# ISP_CCDC register map
Vendor: Texas Instruments
Peripheral module from a debugger description file (folder omap36xx).
Registers are 32-bit, read-write, reset 0x0 unless marked. A register's access mark holds for its fields unless they carry their own. Offsets are as the file gives them; lines under a group give offsets from that group; [hi:lo] are bit positions; {n}, {i} and the like mark numbered series; 'fields as' and 'values as' point back to an identical list; <NAME> marks a mode.

## ISP_CCDC
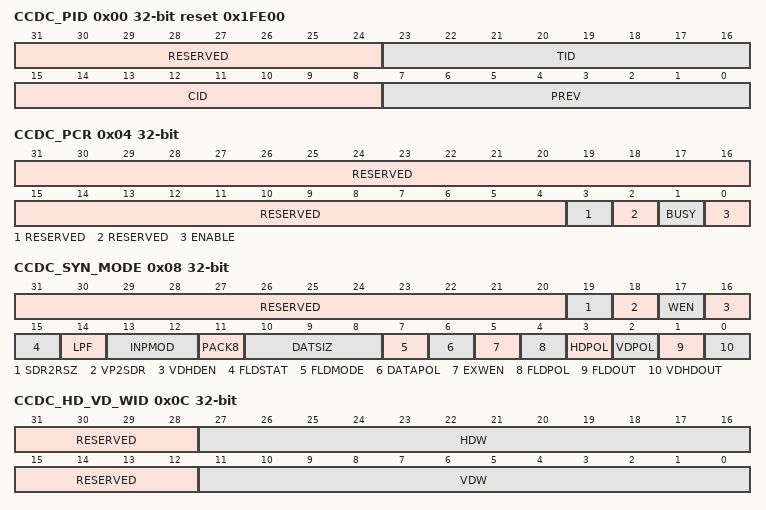
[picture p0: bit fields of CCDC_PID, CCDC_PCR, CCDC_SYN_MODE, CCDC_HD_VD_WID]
0x00 CCDC_PID ro reset 0x1FE00 (reset mask 0xFFFFFF00) — PERIPHERAL ID REGISTER
  [31:24] RESERVED — Write 0s for future compatibility. Reads returns 0.
  [23:16] TID — Peripheral identification: CCDC module
  [15:8] CID — Class identification: Camera ISP
  [7:0] PREV — Peripheral revision number
0x04 CCDC_PCR access per field — PERIPHERAL CONTROL REGISTER
  [31:4] RESERVED rw — Write 0s for future compatibility.Reads returns 0.
  [3] RESERVED rw — Write 0s for future compatibility. Read returns 0.
  [2] RESERVED rw — Write 0s for future compatibility. Read returns 0.
  [1] BUSY ro — CCDC module busy.
    0=Module is not busy; 1=Module is busy
  [0] ENABLE rw — CCDC module enable.This bit is latched by VD (start of frame)
    0=Disable module; 1=Enable module
0x08 CCDC_SYN_MODE access per field — SYNC and mode set register
  [31:20] RESERVED rw — Write 0s for future compatibility.Reads returns 0.
  [19] SDR2RSZ rw — Memory port output into the RESIZER input. Controls whether or not the memory port output data are forwarded to the RESIZER module input port. This does not depend on the state of the CCDC_SYN_MODE.WEN bit. This bit must only be set if the CCDC module receives directly YUV422 data. The input frame size to the RESIZER module is the same as the output frame size to the memory port. The data are simultaneously written to memory if the WEN bit is set while sending the same data to the RESIZER module. The PREVIEW module can also write to the RESIZER module: this bit takes precedence over the PREVIEW module settings. This bit is latched by the VS sync pulse.
    0=Disable; 1=Enable
  [18] VP2SDR rw — Video port output enable to the output formatter.. Controls whether the video port data is forwarded to the output formatter or not. If CCDC_SYN_MODE .WEN= 1, the video port data is written to memory. Note that if field is set, then SDRAM line (VERT_START.SLVx) and pixel start (HORZ_INFO.SPH) are with respect to the video port output (and not the original input) This bit field is latched by the VS sync pulse.
    0=Disable; 1=Enable
  [17] WEN rw — Data write enable. Controls whether the CCDC module output data are written to memory or not. This bit field is latched by the VS sync pulse.
    0=Disable; 1=Enable
  [16] VDHDEN rw — Timing generator enable. If HS/VS sync pulses are defined as output signals, activates the internal timing generator. If HS/VS sync pulses are defined as input signals, activates internal timing generator to synchronize with HS/VS. This bit must be set to 1 when HS and VS signals are used.
    0=Disable; 1=Enable
  [15] FLDSTAT ro — cam_fld signal status. This bit field applies only if the CCDC module is configured to work in interlaced mode: CCDC_SYN_MODE.FLDMODE = 'interlaced'. It indicates the status of the current field.
    0=Odd field; 1=Even field
  [14] LPF rw — Three-tap low pass (antialiasing) filter enable. This bit field is latched by the VS sync pulse.
    0=Filter is disabled; 1=Filter is enabled
  [13:12] INPMOD rw — cam_d format in SYNC mode. Sets the data input format.
    0=Raw data; 1=YCbCr data on 16 bits. It is required to enable the 8 to 16-bit bridge in the register.; 2=YCbCr data on 8 bits
  [11] PACK8 rw — Data packing. Sets the data packing configuration when the data is written to memory.
    0=Normal mode: 16 bits/pixel; 1=Pack mode: 8 bits/pixel
  [10:8] DATSIZ rw — cam_d signal width in SYNC mode. Valid only when CCDC_SYN_MODE.INPMOD = 'raw data'.
    0=cam_d is 8 bits but the 8 to 16-bit bridge is enabled in the register; 4=cam_d is 12 bits; 5=cam_d is 11 bits; 6=cam_d is 10 bits; 7=cam_d is 8 bits
  [7] FLDMODE rw — cam_fld signal mode.
    0=Progressive mode. cam_fld not used.; 1=Interlaced mode. cam_fld used.
  [6] DATAPOL rw — cam_d signal polarity.
    0=Normal; 1=One's complement
  [5] EXWEN rw — External write enable selection. The cam_wen signal can be used as an external memory write-enable signal. The data is stored to memory only if cam_hs, cam_vs and cam_wen signals are asserted.
    0=cam_wen is not used; 1=cam_wen is used
  [4] FLDPOL rw — cam_fld signal polarity.
    0=Positive; 1=Negative
  [3] HDPOL rw — Sets the cam_hs signal polarity.
    0=Positive; 1=Negative
  [2] VDPOL rw — cam_vs signal polarity
    0=Positive; 1=Negative
  [1] FLDOUT rw — cam_fld signal direction.
    0=Input; 1=Output
  [0] VDHDOUT rw — cam_hs and cam_vs signal directions.
    0=Input; 1=Output
0x0C CCDC_HD_VD_WID — SYNC WIDTH CONTROL REGISTER
  [31:28] RESERVED — Write 0s for future compatibility.Reads returns 0.
  [27:16] HDW — Sets the width of the HS sync pulse if set as output. The width of the pulse is (HDW+1) pixel clocks. Not used when HS/VS sync pulses are input signals (CCDC_SYN_MODE.VDHDOUT = 0). This bit field is latched by the VS sync pulse.
  [15:12] RESERVED — Write 0s for future compatibility.Reads returns 0.
  [11:0] VDW — Sets the width of the VS sync pulse is set as output. The width of the pulse is (VDW+1) lines. Not used when HS/VS sync pulses are input signals (CCDC_SYN_MODE.VDHDOUT = 0). This bit field is latched by the VS sync pulse.
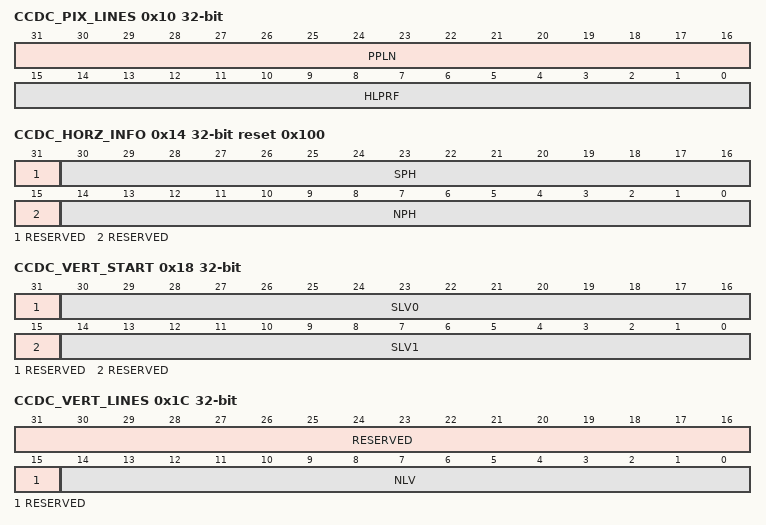
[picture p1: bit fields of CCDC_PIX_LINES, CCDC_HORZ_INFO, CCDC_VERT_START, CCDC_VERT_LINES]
0x10 CCDC_PIX_LINES — SIZE CONTROL REGISTER
  [31:16] PPLN — Pixels per line Sets the number of pixel clock periods in one line. HD period = (PPLN + 1) pixel clocks. Not used when HS/VS sync pulses are input signals (CCDC_SYN_MODE.VDHDOUT = 0). This bit field is latched by the VS sync pulse
  [15:0] HLPRF — Half line per field or frame Sets the number of half lines per frame or field. VD period = (HLPFR + 1)/2 lines. Not used when HS/VS sync pulses are input signals (CCDC_SYN_MODE.VDHDOUT = 0). Sets the internal timing generator to generate the correct number of HS pulses in between two VS pulses. If the sensor is interlaced, with a total of N lines, then this field must be set to N. This means that N half lines are written for each field. If the sensor is progressive, then this register must be set to be twice the number of lines to be written. For example, if sensor outputs N lines, this field must be set to 2N. This bit field is latched by the VS sync pulse.
0x14 CCDC_HORZ_INFO reset 0x100 — HORIZONTAL PIXEL INFO REGISTER
  [31] RESERVED — Write 0s for future compatibility.Reads returns 0.
  [30:16] SPH — Start pixel horizontal Sets the pixel clock position at which data output to memory begins. It is measured from the start of HS. This bit field is latched by the VS sync pulse.
  [15] RESERVED — Write 0s for future compatibility.Reads returns 0.
  [14:0] NPH — Number of pixels horizontal Sets the number of horizontal pixels output to memory. The number of pixels output is (NPH + 1). This bit field is latched by the VS sync pulse.
0x18 CCDC_VERT_START — VERTICAL LINE START REGISTER
  [31] RESERVED — Write 0s for future compatibility.Reads returns 0.
  [30:16] SLV0 — Start line vertical - field0 Sets the line at which data output to memory begins. It is measured from the start of the VS sync pulse. This bit field is latched by the VS sync pulse.
  [15] RESERVED — Write 0s for future compatibility.Reads returns 0.
  [14:0] SLV1 — Start line vertical - field1 Sets the line at which data output to memory begins. It is measured from the start of the VS sync pulse. For a progressive sensor, this bit field is ignored. This bit field is latched by the VS sync pulse.
0x1C CCDC_VERT_LINES — VERTICAL LINE NUMBER REGISTER
  [31:15] RESERVED — Write 0s for future compatibility.Reads returns 0.
  [14:0] NLV — Number of lines - vertical direction Sets the number of vertical lines output to memory. The number of lines output is (NLV + 1). This bit is latched by the VS sync pulse.
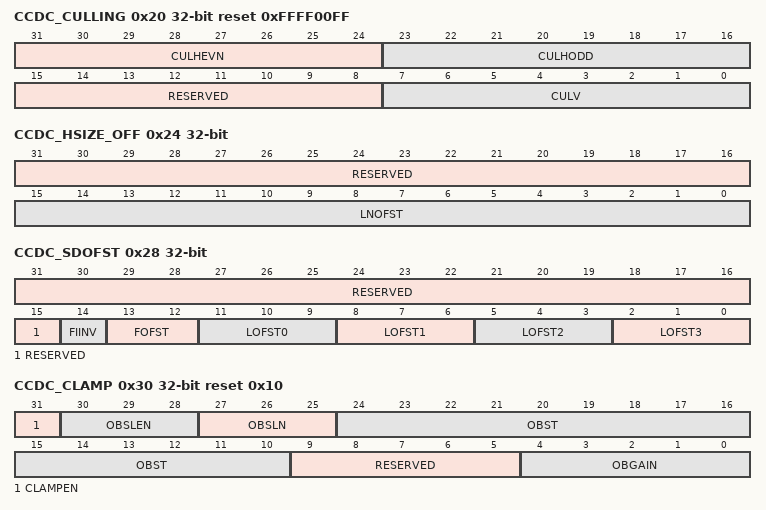
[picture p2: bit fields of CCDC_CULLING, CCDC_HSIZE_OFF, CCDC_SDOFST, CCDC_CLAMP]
0x20 CCDC_CULLING reset 0xFFFF00FF — CULL CONTROL REGISTER
  [31:24] CULHEVN — Horizontal culling patterns for even lines. Sets an 8-bit mask (0:cull, 1:retain). The LSB is the 1st pixel and the MSB is the 8th pixel. Then, the pattern repeats. This bit field is latched by the VS sync pulse.
  [23:16] CULHODD — Horizontal culling patterns for odd lines. Sets an 8-bit mask (0:cull, 1:retain). The LSB is the 1st pixel and the MSB is the 8th pixel. Then, the pattern repeats. This bit field is latched by the VS sync pulse.
  [15:8] RESERVED — Write 0s for future compatibility.Reads returns 0.
  [7:0] CULV — Vertical culling pattern. Sets an 8-bit mask (0:cull, 1:retain). The LSB is the 1st line and the MSB is the 8th line. Then, the pattern repeats. This bit field is latched by the VS sync pulse.
0x24 CCDC_HSIZE_OFF — HORIZONTAL SIZE REGISTER
  [31:16] RESERVED — Write 0s for future compatibility.Reads returns 0.
  [15:0] LNOFST — Line offset. Sets the offset for each output line to memory. The offset must be a multiple of 32 bytes: the 5 least significant bits are ignored. Usually the line offset is equal to the line length in bytes, that is, the line length must be a multiple of 32 bytes. If LNOFST = 0, the data is written again and again over the same line. For optimal performance in the system, the address offset must be on a 256-byte boundary. This bit field is latched by the VS sync pulse.
0x28 CCDC_SDOFST — MEMORY OFFSET REGISTER
  [31:15] RESERVED — Write 0s for future compatibility.Reads returns 0.
  [14] FIINV — Field identification signal inverse This bit field is latched by the VS sync pulse.
    0=Non inverse; 1=Inverse
  [13:12] FOFST — Line offset value This bit field is latched by the VS sync pulse.
    0=+1 line; 1=+2 lines; 2=+3 lines; 3=+4 lines
  [11:9] LOFST0 — Line offset values of even lines and even fields(field id = 0). This bit field is latched by the VS sync pulse.
    0=+1 line; 1=+2 lines; 2=+3 lines; 3=+4 lines; 4=-1 line; 5=-2 lines; 6=-3 lines; 7=-4 lines
  [8:6] LOFST1 — Line offset values of odd lines and even fields(field id = 0). This bit field is latched by the VS sync pulse.
    values as LOFST0
  [5:3] LOFST2 — Line offset values of even lines and odd fields(field id = 1). This bit field is latched by the VS sync pulse.
    values as LOFST0
  [2:0] LOFST3 — Line offset values of odd lines and odd fields(field id = 1). This bit field is latched by the VS sync pulse.
    values as LOFST0
0x2C CCDC_SDR_ADDR — MEMORY ADDRESS REGISTER
  [31:0] ADDR — Memory address Sets the CCDC module output address. The address should be aligned on a 32-byte boundary: the 5 least significant bits are ignored. For optimal performance in the system, the address must be on a 256-byte boundary. This bit field is latched by the VS sync pulse.
0x30 CCDC_CLAMP reset 0x10 — CLAMP CONTROL REGISTER
  [31] CLAMPEN — Clamp enable Enables clamping based on the calculated average of optical black sample. This bit is latched by the VS sync pulse.
    0=Disable; 1=Enable
  [30:28] OBSLEN — Optical black sample length Sets the number of optical black sample pixels per line to include in the average calculation.
    0=1 pixel; 1=2 pixels; 2=4 pixels; 3=8 pixels; 4=16 pixels
  [27:25] OBSLN — Optical black sample lines Sets the number of optical black sample lines to include in the average calculation.
    0=1 line; 1=2 lines; 2=4 lines; 3=8 lines; 4=16 lines
  [24:10] OBST — Start pixel of optical black samples Start pixel position of optical black samples specified from the start of HS in pixel clocks.
  [9:5] RESERVED — Write 0s for future compatibility.Reads returns 0.
  [4:0] OBGAIN — Gain to apply to the optical black average The gain value is in U5Q4 fixed point representation (0 to 1.9375).
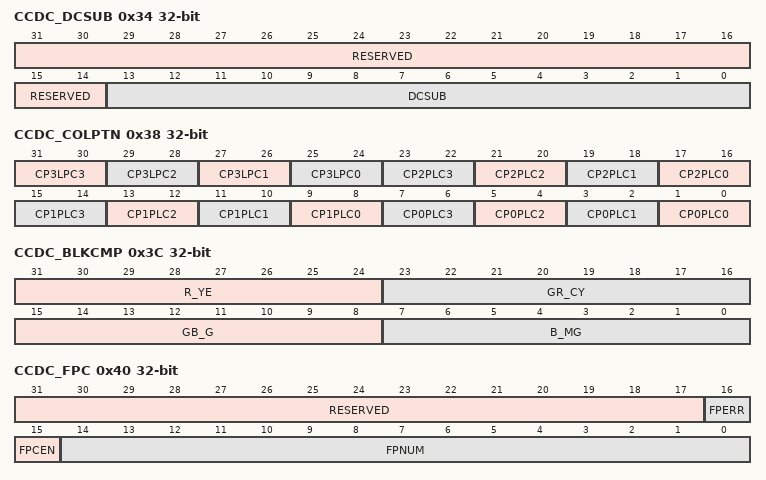
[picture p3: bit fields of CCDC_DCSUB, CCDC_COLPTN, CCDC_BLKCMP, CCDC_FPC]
0x34 CCDC_DCSUB — DC CLAMP REGISTER
  [31:14] RESERVED — Write 0s for future compatibility.Reads returns 0.
  [13:0] DCSUB — DC value to subtract from the data. Sets the DC value to be subtracted from the data when optical black sampling is disabled: CCDC_CLAMP.CLAMPEN = 0 NOTE: In ISP2 thas is the legacy device, this function does not clip negative results to 0 for YUV 8 bit input or REC656 input modes (CCDC_SYN_MODE.INPMOD == 2 || CCDC_REC656IF.R656ON == 1).
0x38 CCDC_COLPTN — COLOR PATTERN REGISTER
  [all] fields
    0=R/Ye; 1=Gr/Cy; 2=Gb/G; 3=B/Mg
  [31:30] CP3LPC3 — Color pattern, 3rd line, pixel counter = 0
  [29:28] CP3LPC2 — Color pattern, 3rd line, pixel counter = 2
  [27:26] CP3LPC1 — Color pattern, 3rd line, pixel counter = 1
  [25:24] CP3LPC0 — Color pattern, 3rd line, pixel counter = 0
  [2n+17:2n+16] CP2PLC{n} (n=0..3) — Color pattern, 2nd line, pixel counter = {n}
  [2n+9:2n+8] CP1PLC{n} (n=0..3) — Color pattern, 1st line, pixel counter = {n}
  [2n+1:2n] CP0PLC{n} (n=0..3) — Color pattern, 0th line, pixel counter = {n}
0x3C CCDC_BLKCMP — BLACK COMPENSATION REGISTER
  [31:24] R_YE — Black-level compensation, R/Ye pixels. 2's complement, MSB is sign bit. The range is -128 to +127.
  [23:16] GR_CY — Black-level compensation, Gr/Cy pixels. 2's complement, MSB is sign bit. The range is -128 to +127.
  [15:8] GB_G — Black-level compensation, Gb/G pixels. 2's complement, MSB is sign bit. The range is -128 to +127.
  [7:0] B_MG — Black-level compensation, B/Mg pixels. 2's complement, MSB is sign bit. The range is -128 to +127.
0x40 CCDC_FPC — FAULT PIXEL CORRECTION REGISTER
  [31:17] RESERVED — Write 0s for future compatibility.Reads returns 0.
  [16] FPERR — Fault pixel correction error This bit is set when the CCDC module is unable to fetch the required fault pixel table entry in time. Write 1 to clear the error or end_of_frame clears it automatically for the next frame. For example, the current pixel being processed has coordinates of 256/512 (256th line and 512th pixel in that line) and it must be corrected. If the entry in the fault pixel table that must be used has coordinates 256/256, then the current pixel cannot be corrected since the correct entry is not loaded in time. Note that there is no error recovery mechanism in the CCDC; if this bit is set at anytime in a frame, there are no more fault pixels corrected in that frame. Firmware is responsible for making sure that there is enough bandwidth in the system to allow for loading of the fault pixel table. Alternately, decreasing the frequency of the fault pixels to be corrected enhances the chances of this bit not being set.
    0=No error; 1=Error
  [15] FPCEN — Fault pixel correction enable. Upon setting this bit, and as long as it remains enabled, the fault pixel logic continues to request data and just start over for next frame once the last data of current frame has been received. As soon as the register is set the data are fetched. To disable fault pixel correction, users can write a 0 at any time. However, the disabling only applies after the current frame is processed (busy bit for current frame is 0) This bit should only be written after the FPC_ADDR register below has been set. Also, the other fields in this register have to be set prior to enabling this bit. The required process is: Write(FPC_ADDR)Write(FPC) with this bit (FPC.FPCEN) turned offWrite(FPC) with this bit (FPC.FPCEN) turned on while other fields are same as previous write
    0=Disable; 1=Enable
  [14:0] FPNUM — Number of fault pixels to be corrected in the frame This field should not be changed when the FPCEN is enabled at any time
0x44 CCDC_FPC_ADDR — FAULT PIXEL CORRECTION MEMORY ADDRESS
  [31:0] ADDR — Memory address Set the memory address of the fault pixel correction table. The address should be aligned to a 64-byte boundary: the 6 LSBs are ignored. Each of the 32-bit table entry contains a 13-bit vertical position, a 14-bit horizontal position and a 5-bit operation field.
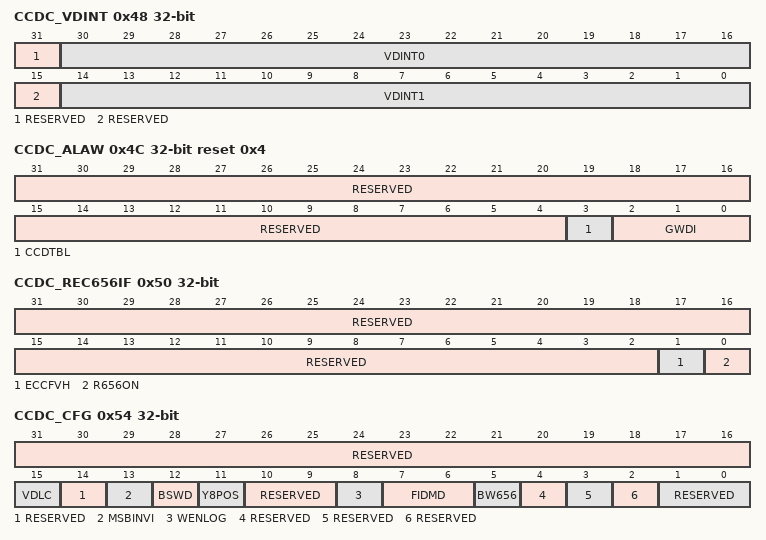
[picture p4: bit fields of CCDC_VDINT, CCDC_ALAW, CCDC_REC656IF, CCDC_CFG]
0x48 CCDC_VDINT — VD INTERRUPT REGISTER
  [31] RESERVED — Write 0s for future compatibility.Reads returns 0.
  [30:16] VDINT0 — VD0 interrupt timing Specified VDINT0 in units of horizontal lines from the start of the VS sync pulse. The resulting value is VDINT0+1. Note that if the rising edge (or falling edge if programmed) of the HS sync pulse lines up with the rising edge (or falling edge if programmed) of VS sync pulse, the first HS sync pulse is not counted.
  [15] RESERVED — Write 0s for future compatibility.Reads returns 0.
  [14:0] VDINT1 — VD1 interrupt timing Specifies VDINT1 in units of horizontal lines from the start of the VS sync pulse. The resulting value is VDINT1+1. Note that if the rising edge (or falling edge if programmed) of the HS sync pulse lines up with the rising edge (or falling edge if programmed) of VS sync pulse, the first HS sync pulse is not counted.
0x4C CCDC_ALAW reset 0x4 — ALAW SETTINGS REGISTER
  [31:4] RESERVED — Write 0s for future compatibility.Reads returns 0.
  [3] CCDTBL — Apply A-Law compression to data saved to memory.
    0=Disable; 1=Enable
  [2:0] GWDI — A-Law input width
    3=Bits 12 to 3; 4=Bits 11 to 2; 5=Bits 10 to 1; 6=Bits 9 to 0
0x50 CCDC_REC656IF — ITU-R BT.656 CONFIGURATION REGISTER
  [31:2] RESERVED — Write 0s for future compatibility.Reads returns 0.
  [1] ECCFVH — FVH error correction enable
    0=Disable; 1=Enable
  [0] R656ON — ITU-R BT656 interface enable
    0=Disable; 1=Enable
0x54 CCDC_CFG — CONFIGURATION REGISTER
  [31:16] RESERVED — Write 0s for future compatibility.Reads returns 0.
  [15] VDLC — Enable latching function registers on the internal VS sync pulse. If this bit is set, all the register fields that are VS pulse latched take on new values immediately. Care should be taken not to alter fields that can cause undesired behavior to the output data NOTE: In ISP2 that is in the legacy device, this bit must be set to 1 by software if the CCDC is to be used. If CCDCFG.VDLC remains set to 0 (default), indeterminate results may occur for ANY register access in the CCDC. For details, see , .
    0=Latched on VS; 1=Not latched on VS
  [14] RESERVED — Write 0s for future compatibility.Reads returns 0.
  [13] MSBINVI — MSB of chroma input signal stored to memory inverted.
    0=Normal; 1=MSB inverted
  [12] BSWD — Byte swap data stored to memory.
    0=Normal; 1=Swap bytes
  [11] Y8POS — Location of Y color component when YCbCr 8-bit data is input.
    0=Even pixel; 1=Odd pixel
  [10:9] RESERVED — Write 0s for future compatibility.Reads returns 0.
  [8] WENLOG — Valid area settings
    0=Internal valid signal and WEN signal are ANDed logically; 1=Internal valid signal and WEN signal are ORed logically
  [7:6] FIDMD — Settings of field identification detection function.
    0=FLD signal is latched at the VS timing. The external Field signal is latched when the VD is active and the active edge of the HD signal; 1=FLD signal is not latched. The field signal is not latched at all; 2=FLD signal is latched at edge of VS. The field signal is latched on the active edge of the VD signal; 3=FLD signal is latched on phase of VS and HS. The field signal is latched when the VD signal is active and the HD signal is inactive (opposite phase)
  [5] BW656 — The data width in ITU-R BT656 input mode. This bit field takes precedence over the CCDC_SYN_MODE.INPMOD and CCDC_DATSIZ bit fields if the ITU mode is enabled with CCDC_REC656IF.R656ON = 1.
    0=8 bits; 1=10 bits
  [4] RESERVED — Write 0s for future compatibility.Reads returns 0.
  [3] RESERVED — Write 0s for future compatibility.Reads returns 0.
  [2] RESERVED — Write 0s for future compatibility.Reads returns 0.
  [1:0] RESERVED — Write 0s for future compatibility.Reads returns 0.
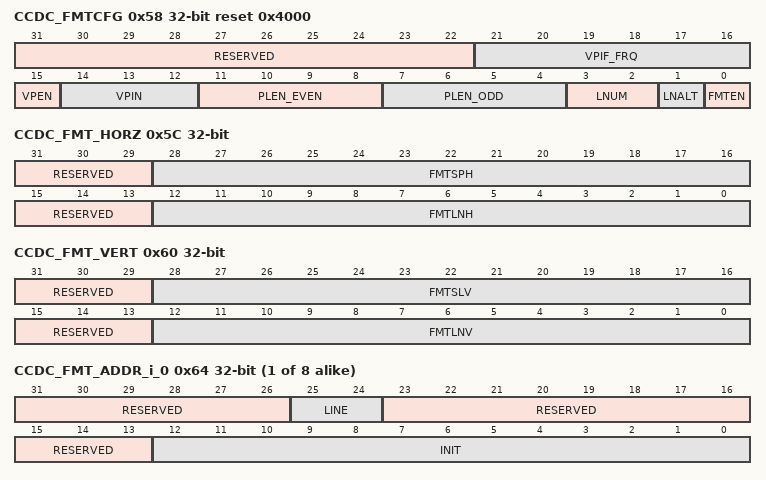
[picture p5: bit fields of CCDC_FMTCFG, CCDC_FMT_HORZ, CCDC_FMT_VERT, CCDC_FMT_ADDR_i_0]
0x58 CCDC_FMTCFG access per field reset 0x4000 — DATA REFORMATTER/VIDEO IF CONFIG REGISTER
  [31:22] RESERVED ro — Write 0s for future compatibility. Read returns 0.
  [21:16] VPIF_FRQ rw — Video port data ready frequency. This field allows the firmware to control the rate at which the video port delivers new data to the other modules (PREVIEW, H3A, and HIST modules). In effect, this register controls the raw output bandwidth of the PREVIEW, H3A, and HIST. Depending on the input sensor clock, the user can set this field appropriately and balance the bandwidth requirements to memory. Given a pixel clock, one shall set this bit field with the higher divisor value to lower the memory bandwidth requirement. The video port clock is Interconnect/(VPIF_FRQ+2).The valid range for VPIF_FRQ is 0..62
  [15] VPEN rw — Video port enable. This bit shall be enabled to send data to the PREVIEW, H3A and HIST modules.
    0=Disable; 1=Enable
  [14:12] VPIN rw — 10-bit input select for video port.
    3=bits 12-3; 4=bits 11-2; 5=bits 10-1; 6=bits 9-0
  [11:8] PLEN_EVEN rw — Number of program entries in even line minus 1. If the desired number of program entries is 8, then the value shall be set to 7.
  [7:4] PLEN_ODD rw — Number of program entries in odd line minus 1. If the desired number of program entries is 8, then the value shall be set to 7.
  [3:2] LNUM rw — Number of output lines from 1 input line
    0=1 line; 1=2 lines; 2=3 lines; 3=4 lines
  [1] LNALT rw — Line alternating mode enable.In Line Alternating Mode, even and odd lines are swapped. 0th line output as 1st line and 1st line output as 0th line, and so on. If this bit field is set, the start and number of lines for the formatter (FMTVERT below) should be even. The FMTEN field below should be set in addition for this field to function
    0=Enable. Normal mode; 1=Disable. Line alternating mode
  [0] FMTEN rw — Formatter enable. This bit is latched by the VS sync pulse.
    0=Disable; 1=Enable
0x5C CCDC_FMT_HORZ — DATA REFORMATTER HORIZ INFO REGISTER
  [31:29] RESERVED — Write 0s for future compatibility.Reads returns 0.
  [28:16] FMTSPH — Start pixel horizontal from start of the HS sync pulse.
  [15:13] RESERVED — Write 0s for future compatibility.Reads returns 0.
  [12:0] FMTLNH — Number of pixels in horizontal direction to use for the data reformatter (minimum is 2 pixels).
0x60 CCDC_FMT_VERT — DATA REFORMATTER VERT INFO REGISTER
  [31:29] RESERVED — Write 0s for future compatibility.Reads returns 0.
  [28:16] FMTSLV — Start line from start of VS sync pulse for the data reformatter.
  [15:13] RESERVED — Write 0s for future compatibility.Reads returns 0.
  [12:0] FMTLNV — Number of lines in vertical direction for the data reformatter
{0x64+4i} CCDC_FMT_ADDR_i_{i} (i=0..7) — DATA REFORMATTER ADDR PTR x SETUP REGISTER
  [31:26] RESERVED — Write 0s for future compatibility.Reads returns 0.
  [25:24] LINE — The output line the address belongs to is the 1st, 2nd, 3rd or 4th line.
    0=1st line; 1=2nd line; 2=3rd line; 3=4th line
  [23:13] RESERVED — Write 0s for future compatibility.Reads returns 0.
  [12:0] INIT — Initial address value If CCDC_FMTCFG.LNUM = 0 (1 line), the max value of the address must not exceed (4x1376 - 1) including the updates on it during processing. If CCDC_FMTCFG.LNUM = 1 (2 lines), the max value of the address must not exceed (3x1376 - 1) including the updates on it during processing. If CCDC_FMTCFG.LNUM = 2 (3 lines), the max value of the address must not exceed (2x1376 - 1) including the updates on it during processing. If CCDC_FMTCFG.LNUM = 3 (4 lines), the max value of the address must not exceed (1x1376 - 1) including the updates on it during processing. The address must always be a positive number during the updates.
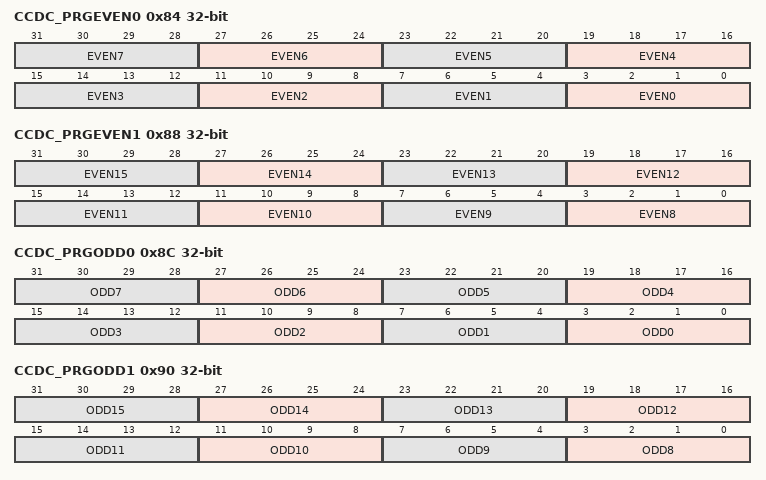
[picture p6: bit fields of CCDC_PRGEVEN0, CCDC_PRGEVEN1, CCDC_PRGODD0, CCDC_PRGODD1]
0x84 CCDC_PRGEVEN0 — PROGRAM ENTRIES 0-7 FOR EVEN LINES REGISTER Each bit field in this register is programmed in the same way. The following definition applies, where n ranges from 0 to 8. Bits [4*n+3:4*n+1] 000: ADDR0 001: ADDR1 010: ADDR2 011: ADDR3 100: ADDR4 101: ADDR5 110: ADDR6 111: ADDR7 Bit [4*n]: 0: Auto increment 1: Auto decrement
  [4n+3:4n] EVEN{n} (n=0..7) — Address update. See register description.
0x88 CCDC_PRGEVEN1 — PROGRAM ENTRIES 8-15 FOR EVEN LINES REGISTER Each bit field in this register is programmed in the same way. The following definition applies, where n ranges from 0 to 8. Bits [4*n+3:4*n+1] 000: ADDR0 001: ADDR1 010: ADDR2 011: ADDR3 100: ADDR4 101: ADDR5 110: ADDR6 111: ADDR7 Bit [4*n]: 0: Auto increment 1: Auto decrement
  [4n-29:4n-32] EVEN{n} (n=8..15) — Address update. See register description.
0x8C CCDC_PRGODD0 — PROGRAM ENTRIES 0-7 FOR ODD LINES REGISTER Each bit field in this register is programmed in the same way. The following definition applies, where n ranges from 0 to 8. Bits [4*n+3:4*n+1] 000: ADDR0 001: ADDR1 010: ADDR2 011: ADDR3 100: ADDR4 101: ADDR5 110: ADDR6 111: ADDR7 Bit [4*n]: 0: Auto increment 1: Auto decrement
  [4n+3:4n] ODD{n} (n=0..7) — Address update. See register description.
0x90 CCDC_PRGODD1 — PROGRAM ENTRIES 8-15 FOR ODD LINES REGISTER Each bit field in this register is programmed in the same way. The following definition applies, where n ranges from 0 to 8. Bits [4*n+3:4*n+1] 000: ADDR0 001: ADDR1 010: ADDR2 011: ADDR3 100: ADDR4 101: ADDR5 110: ADDR6 111: ADDR7 Bit [4*n]: 0: Auto increment 1: Auto decrement
  [4n-29:4n-32] ODD{n} (n=8..15) — Address update. See register description.
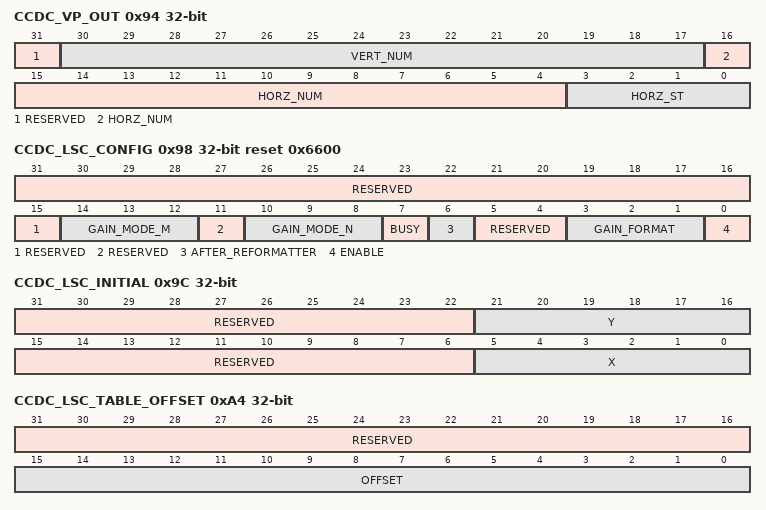
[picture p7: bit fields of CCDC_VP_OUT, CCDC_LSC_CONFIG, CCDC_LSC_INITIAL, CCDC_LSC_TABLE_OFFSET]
0x94 CCDC_VP_OUT — VIDEO PORT OUTPUT REGISTER
  [31] RESERVED — Write 0s for future compatibility.Reads returns 0.
  [30:17] VERT_NUM — Number of vertical lines to clock out the video. If the data reformatter is turned off, then the number of lines that can be clocked out of the video port must be at least 1 line less than the number of lines input from the sensor. If the data reformatter is turned on, then the number of lines that can be clocked out of the video port must be less than(CCDC_FMT_VERT.FMTLNV - 1) * (CCDC_FMTCFG.LNUM + 1) The video port output VS pulse is generated right from the first video port input VS itself.
  [16:4] HORZ_NUM — Number of horizontal pixel to clock out the video port. The minimum value allowed is 2 pixels. The maximum offset allowed is 1376 if original input is broken down to 4 lines. The maximum offset allowed is 1376 if original input is broken down to 3 lines. The maximum offset allowed is 2*1376 if original input is broken down to 2 lines. The maximum offset allowed is 4*1376 if original input is broken down to 1 line.
  [3:0] HORZ_ST — Horizontal start pixel in each output line. The maximum value allowed is 15. The video port output HSYNC pulse is generated from this position on for each line. To be able to select an offset higher than 15, the input settings to the data reformatter must be configured appropriately. The purpose of this parameter is to allow for sensors that can read out a parallelogram image rather than a rectangular image.
0x98 CCDC_LSC_CONFIG access per field reset 0x6600 — LENS SHADING COMPENSATION CONTROL AND STATUS REGISTER
  [31:15] RESERVED rw — Write 0s for future compatibility. Read returns 0.
  [14:12] GAIN_MODE_M rw — Define the horizontal dimension of a paxel. Possiblevalues are listed below
    2=Paxel is 4 pixels tall (M=4); 3=Paxel is 8 pixels tall (M=8); 4=Paxel is 16 pixels tall (M=16); 5=Paxel is 32 pixels tall (M=32); 6=Paxel is 64 pixels tall (M=64)
  [11] RESERVED ro — Write 0s for future compatibility. Read returns 0.
  [10:8] GAIN_MODE_N rw — Define the vertical dimension of a paxel. Possible values are listed below
    2=Paxel is 4 pixels tall (N=4); 3=Paxel is 8 pixels tall (N=8); 4=Paxel is 16 pixels tall (N=16); 5=Paxel is 32 pixels tall (N=32); 6=Paxel is 64 pixels tall (N=64)
  [7] BUSY ro — Module busy or idle
    0=The module is idle; 1=The module is busy
  [6] AFTER_REFORMATTER rw — Chooses if lens-shading compensation is done before or after data reformatting
    0=Lens-shading is done before data reformatting. H3A, HIST and PREVIEW receives shading compensated data; 1=Data received by H3A is not compensated. Data received by PREVIEW and HIST is compensated.
  [5:4] RESERVED rw — Write 0s for future compatibility. Reads return 0.
  [3:1] GAIN_FORMAT rw — Sets gain table format
    0=Coded as 8-bit fraction Range from 0 to 255/256; 1=Coded as 8-bit fraction + 1.0 of base. Range from 1 to 1+255/256; 2=Coded as 1-bit integer, 7-bit fraction. Range from 0 to 1+127/128; 3=Coded as 1-bit integer, 7-bit fraction + 1.0 Range from 1 to 2+127/128; 4=Coded as 2-bit integer, 6-bit fraction Range from 0 to 3+63/64; 5=Coded as 2-bit integer, 6-bit fraction + 1.0 Range from 1 to 4+63/64; 6=Coded as 3-bit integer, 5-bit fraction Range from 0 to 7+31/32; 7=Coded as 3-bit integer, 5-bit fraction + 1.0 Range from 1 to 8+31/32
  [0] ENABLE rw — Enables/disables LSC
    0=Disables the module at the end of the current frame. Video data is transmitted without modification when LSC is disabled. The BUSY bit can be used to poll when access to SBL buffer can be used by the preview module.; 1=Enables the module. Module starts fetching the gain table as soon it is started. Firmware has to make sure it has been correctly initialized before starting the module. Data processing is only effective at the start of the next frame. Note that preview module dark frame subtract must be disabled because there is only one shared read port.
0x9C CCDC_LSC_INITIAL — LENS SHADING COMPENSATION INITIAL X/Y REGISTER
  [31:22] RESERVED — Write 0s for future compatibility. Reads return 0.
  [21:16] Y — Y position, in pixels, of the first active pixel in referenceto the first active paxel. Must be an even number.
  [15:6] RESERVED — Write 0s for future compatibility. Reads return 0.
  [5:0] X — X position, in pixels, of the first active pixel in referenceto the first active paxel. Must be an even number.
0xA0 CCDC_LSC_TABLE_BASE — LENS SHADING COMPENSATION TABLE BASE ADDRESS REGISTER
  [31:0] BASE — Table address in bytes. Table is 32-bit aligned so this register must be a multiple of 4.This bit field sets the address of the gain table in memory.
0xA4 CCDC_LSC_TABLE_OFFSET — LENS SHADING COMPENSATION TABLE OFFSET REGISTER
  [31:16] RESERVED — Write 0s for future compatibility. Read returns 0.
  [15:0] OFFSET — Defines the length, in bytes, of one row of the gain table. Gain table is 32-bit aligned, so this value must be a multiple of 4.Note that the row in memory must be longer or equal to what LSC uses.
